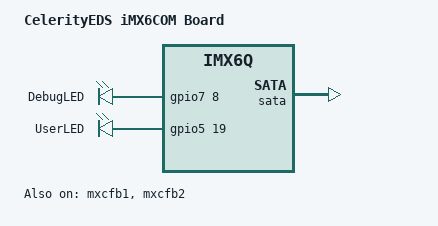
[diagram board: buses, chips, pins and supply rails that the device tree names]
/*
 * Copyright 2013 Freescale Semiconductor, Inc.
 *
 * Author: Fabio Estevam <fabio.estevam@freescale.com>
 *
 * This program is free software; you can redistribute it and/or modify
 * it under the terms of the GNU General Public License version 2 as
 * published by the Free Software Foundation.
 *
 */
/dts-v1/;
#include "imx6q.dtsi"
#include "imx6qdl-imx6com.dtsi"
#include <dt-bindings/gpio/gpio.h>

/ {
	model = "CelerityEDS iMX6COM Board";
	compatible = "fsl,imx6q";

	leds {
		compatible = "gpio-leds";
		debug-led {
			label = "DebugLED";		/* Debug LED D9 on iMX6COM */
			gpios = <&gpio7 8 0>;
		};
		user-led {
			label = "UserLED";		/* User LED D2 on COM Carrier Board */
			gpios = <&gpio5 19 0>;
		};
	};
};

&sata {
	status = "okay";
};

&ldb {
	ipu_id = <0>;
	sec_ipu_id = <0>;
};

&mxcfb1 {
	status = "okay";
};

&mxcfb2 {
	status = "okay";
};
